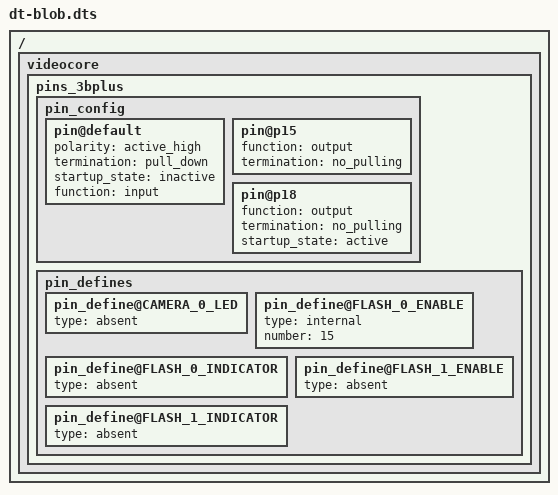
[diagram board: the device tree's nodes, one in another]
/dts-v1/;

/ {
   videocore {

      pins_3bplus {
         pin_config {
            pin@default {
               polarity = "active_high";
               termination = "pull_down";
               startup_state = "inactive";
               function = "input";
            }; // pin
            pin@p15 { function = "output"; termination = "no_pulling"; };
            pin@p18 { function = "output"; termination = "no_pulling"; startup_state = "active"; };
         }; // pin_config

         pin_defines {
            pin_define@CAMERA_0_LED {
               type = "absent";
            };
            pin_define@FLASH_0_ENABLE {
               type = "internal";
               number = <15>;
            };
            pin_define@FLASH_0_INDICATOR {
               type = "absent";
            };
            pin_define@FLASH_1_ENABLE {
               type = "absent";
            };
            pin_define@FLASH_1_INDICATOR {
               type = "absent";
            };
         }; // pin_defines
      }; // pins
   };
};
